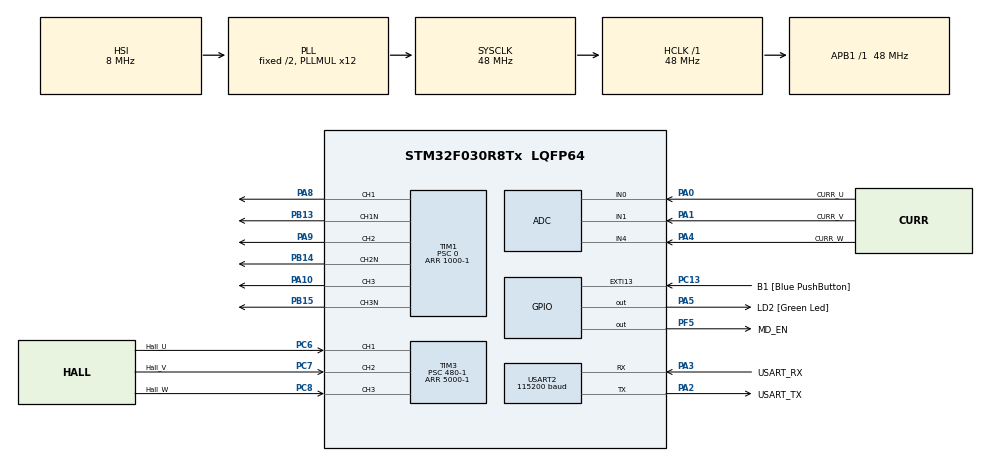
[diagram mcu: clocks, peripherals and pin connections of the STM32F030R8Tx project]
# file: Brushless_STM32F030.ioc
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ADC.ContinuousConvMode=DISABLE
ADC.DMAContinuousRequests=DISABLE
ADC.DiscontinuousConvMode=DISABLE
ADC.EOCSelection=ADC_EOC_SINGLE_CONV
ADC.ExternalTrigConv=ADC_EXTERNALTRIGCONV_T1_TRGO
ADC.ExternalTrigConvEdge=ADC_EXTERNALTRIGCONVEDGE_RISING
ADC.Overrun=ADC_OVR_DATA_OVERWRITTEN
ADC.SamplingTime=ADC_SAMPLETIME_1CYCLE_5
ADC.ScanConvMode=ADC_SCAN_DIRECTION_FORWARD
Mcu.Family=STM32F0
Mcu.Name=STM32F030R8Tx
Mcu.Package=LQFP64
NVIC.ADC1_IRQn=true\:2\:0\:true\:false\:true\:true\:true
NVIC.TIM3_IRQn=true\:0\:0\:false\:false\:true\:true\:true
NVIC.TIM6_IRQn=true\:3\:0\:true\:false\:true\:true\:true
NVIC.USART2_IRQn=true\:1\:0\:true\:false\:true\:true\:true
PA0.GPIO_Label=CURR_U
PA0.Mode=IN0
PA0.Signal=ADC_IN0
PA1.GPIO_Label=CURR_V
PA1.Mode=IN1
PA1.Signal=ADC_IN1
PA10.Signal=S_TIM1_CH3
PA13.GPIO_Label=TMS
PA13.Mode=Serial_Wire
PA13.Signal=SYS_SWDIO
PA14.GPIO_Label=TCK
PA14.Mode=Serial_Wire
PA14.Signal=SYS_SWCLK
PA2.GPIO_Label=USART_TX
PA2.GPIO_Mode=GPIO_MODE_AF_PP
PA2.GPIO_PuPd=GPIO_NOPULL
PA2.GPIO_Speed=GPIO_SPEED_FREQ_LOW
PA2.Mode=Asynchronous
PA2.Signal=USART2_TX
PA3.GPIO_Label=USART_RX
PA3.GPIO_Mode=GPIO_MODE_AF_PP
PA3.GPIO_PuPd=GPIO_NOPULL
PA3.GPIO_Speed=GPIO_SPEED_FREQ_LOW
PA3.Mode=Asynchronous
PA3.Signal=USART2_RX
PA4.GPIO_Label=CURR_W
PA4.Mode=IN4
PA4.Signal=ADC_IN4
PA5.GPIO_Label=LD2 [Green Led]
PA5.GPIO_Mode=GPIO_MODE_OUTPUT_PP
PA5.GPIO_PuPd=GPIO_NOPULL
PA5.GPIO_Speed=GPIO_SPEED_FREQ_LOW
PA5.Signal=GPIO_Output
PA8.Signal=S_TIM1_CH1
PA9.Signal=S_TIM1_CH2
PB13.Mode=PWM Generation1 CH1 CH1N
PB13.Signal=TIM1_CH1N
PB14.Mode=PWM Generation2 CH2 CH2N
PB14.Signal=TIM1_CH2N
PB15.Mode=PWM Generation3 CH3 CH3N
PB15.Signal=TIM1_CH3N
PC13.GPIO_Label=B1 [Blue PushButton]
PC13.GPIO_ModeDefaultEXTI=GPIO_MODE_IT_FALLING
PC13.Signal=GPXTI13
PC14-OSC32_IN.Mode=LSE-External-Oscillator
PC14-OSC32_IN.Signal=RCC_OSC32_IN
PC15-OSC32_OUT.Mode=LSE-External-Oscillator
PC15-OSC32_OUT.Signal=RCC_OSC32_OUT
PC6.GPIO_Label=Hall_U
PC6.GPIO_ModeDefaultPP=GPIO_MODE_AF_OD
PC6.GPIO_PuPd=GPIO_PULLUP
PC6.Signal=S_TIM3_CH1
PC7.GPIO_Label=Hall_V
PC7.GPIO_ModeDefaultPP=GPIO_MODE_AF_OD
PC7.GPIO_PuPd=GPIO_PULLUP
PC7.Signal=S_TIM3_CH2
PC8.GPIO_Label=Hall_W
PC8.GPIO_ModeDefaultPP=GPIO_MODE_AF_OD
PC8.GPIO_PuPd=GPIO_PULLUP
PC8.Signal=S_TIM3_CH3
PF0-OSC_IN.Mode=HSE-External-Clock-Source
PF0-OSC_IN.Signal=RCC_OSC_IN
PF1-OSC_OUT.Signal=RCC_OSC_OUT
PF5.GPIO_Label=MD_EN
PF5.Signal=GPIO_Output
ProjectManager.HeapSize=0x200
ProjectManager.StackSize=0x400
ProjectManager.TargetToolchain=EWARM V8.32
RCC.AHBFreq_Value=48000000
RCC.APB1Freq_Value=48000000
RCC.APB1TimFreq_Value=48000000
RCC.HCLKFreq_Value=48000000
RCC.PLLMUL=RCC_PLL_MUL12
RCC.SYSCLKFreq_VALUE=48000000
RCC.SYSCLKSource=RCC_SYSCLKSOURCE_PLLCLK
SH.S_TIM1_CH1.0=TIM1_CH1,PWM Generation1 CH1 CH1N
SH.S_TIM1_CH2.0=TIM1_CH2,PWM Generation2 CH2 CH2N
SH.S_TIM1_CH3.0=TIM1_CH3,PWM Generation3 CH3 CH3N
SH.S_TIM3_CH1.0=TIM3_CH1,Xored_Inputs_Hall_Sensor_Interface
SH.S_TIM3_CH2.0=TIM3_CH2,Xored_Inputs_Hall_Sensor_Interface
SH.S_TIM3_CH3.0=TIM3_CH3,Xored_Inputs_Hall_Sensor_Interface
TIM1.AutoReloadPreload=TIM_AUTORELOAD_PRELOAD_ENABLE
TIM1.Channel-PWM\ Generation1\ CH1\ CH1N=TIM_CHANNEL_1
TIM1.Channel-PWM\ Generation2\ CH2\ CH2N=TIM_CHANNEL_2
TIM1.Channel-PWM\ Generation3\ CH3\ CH3N=TIM_CHANNEL_3
TIM1.CounterMode=TIM_COUNTERMODE_CENTERALIGNED1
TIM1.Period=1000-1
TIM1.Prescaler=0
TIM1.TIM_MasterOutputTrigger=TIM_TRGO_UPDATE
TIM3.IC1Filter=5
TIM3.Period=5000-1
TIM3.Prescaler=480-1
TIM6.AutoReloadPreload=TIM_AUTORELOAD_PRELOAD_ENABLE
TIM6.Period=10000-1
TIM6.Prescaler=48-1
USART2.BaudRate=115200
USART2.DMADisableonRxErrorParam=ADVFEATURE_DMA_DISABLEONRXERROR
USART2.VirtualMode-Asynchronous=VM_ASYNC
VP_TIM6_VS_ClockSourceINT.Mode=Enable_Timer
board=NUCLEO-F030R8

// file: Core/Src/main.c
/* USER CODE BEGIN Header */
/**
  ******************************************************************************
  * @file           : main.c
  * @brief          : Main program body
  ******************************************************************************
  * @attention
  *
  * <h2><center>&copy; Copyright (c) 2021 STMicroelectronics.
  * All rights reserved.</center></h2>
  *
  * This software component is licensed by ST under BSD 3-Clause license,
  * the "License"; You may not use this file except in compliance with the
  * License. You may obtain a copy of the License at:
  *                        opensource.org/licenses/BSD-3-Clause
  *
  ******************************************************************************
  */
/* USER CODE END Header */
#include "main.h"

/* USER CODE BEGIN Includes */
#include	"Common/Control.h"
#include	"Common/Communication/Communication.h"

#include	"Interface/ML_ADC.h"
#include	"Interface/ML_TIM.h"

/* USER CODE END Includes */

ADC_HandleTypeDef hadc;

TIM_HandleTypeDef htim1;
TIM_HandleTypeDef htim3;
TIM_HandleTypeDef htim6;

UART_HandleTypeDef huart2;

void SystemClock_Config(void);
static void MX_GPIO_Init(void);
static void MX_USART2_UART_Init(void);
static void MX_TIM1_Init(void);
static void MX_TIM3_Init(void);
static void MX_ADC_Init(void);
static void MX_TIM6_Init(void);

int main(void)
{

  /* MCU Configuration--------------------------------------------------------*/

  /* Reset of all peripherals, Initializes the Flash interface and the Systick. */
  HAL_Init();

  /* Configure the system clock */
  SystemClock_Config();

  /* Initialize all configured peripherals */
  MX_GPIO_Init();
  MX_USART2_UART_Init();
  MX_TIM1_Init();
  MX_TIM3_Init();
  MX_ADC_Init();
  MX_TIM6_Init();
  /* USER CODE BEGIN 2 */

	/* Startup */
	TIM_Startup();
	ADC_Startup();

	Ctr_Startup();
	Com_Startup();

  /* USER CODE END 2 */

  /* Infinite loop */
  while (1)
  {

    /* USER CODE BEGIN 3 */
	//Ctr_Task();
	Com_Task();

  }
  /* USER CODE END 3 */
}

void SystemClock_Config(void)
{
  RCC_OscInitTypeDef RCC_OscInitStruct = {0};
  RCC_ClkInitTypeDef RCC_ClkInitStruct = {0};

  /** Initializes the RCC Oscillators according to the specified parameters
  * in the RCC_OscInitTypeDef structure.
  */
  RCC_OscInitStruct.OscillatorType = RCC_OSCILLATORTYPE_HSI|RCC_OSCILLATORTYPE_HSI14;
  RCC_OscInitStruct.HSIState = RCC_HSI_ON;
  RCC_OscInitStruct.HSI14State = RCC_HSI14_ON;
  RCC_OscInitStruct.HSICalibrationValue = RCC_HSICALIBRATION_DEFAULT;
  RCC_OscInitStruct.HSI14CalibrationValue = 16;
  RCC_OscInitStruct.PLL.PLLState = RCC_PLL_ON;
  RCC_OscInitStruct.PLL.PLLSource = RCC_PLLSOURCE_HSI;
  RCC_OscInitStruct.PLL.PLLMUL = RCC_PLL_MUL12;
  RCC_OscInitStruct.PLL.PREDIV = RCC_PREDIV_DIV1;
  if (HAL_RCC_OscConfig(&RCC_OscInitStruct) != HAL_OK)
  {
    Error_Handler();
  }
  /** Initializes the CPU, AHB and APB buses clocks
  */
  RCC_ClkInitStruct.ClockType = RCC_CLOCKTYPE_HCLK|RCC_CLOCKTYPE_SYSCLK
                              |RCC_CLOCKTYPE_PCLK1;
  RCC_ClkInitStruct.SYSCLKSource = RCC_SYSCLKSOURCE_PLLCLK;
  RCC_ClkInitStruct.AHBCLKDivider = RCC_SYSCLK_DIV1;
  RCC_ClkInitStruct.APB1CLKDivider = RCC_HCLK_DIV1;

  if (HAL_RCC_ClockConfig(&RCC_ClkInitStruct, FLASH_LATENCY_1) != HAL_OK)
  {
    Error_Handler();
  }
}

static void MX_ADC_Init(void)
{

  ADC_ChannelConfTypeDef sConfig = {0};

  /** Configure the global features of the ADC (Clock, Resolution, Data Alignment and number of conversion)
  */
  hadc.Instance = ADC1;
  hadc.Init.ClockPrescaler = ADC_CLOCK_ASYNC_DIV1;
  hadc.Init.Resolution = ADC_RESOLUTION_12B;
  hadc.Init.DataAlign = ADC_DATAALIGN_RIGHT;
  hadc.Init.ScanConvMode = ADC_SCAN_DIRECTION_FORWARD;
  hadc.Init.EOCSelection = ADC_EOC_SINGLE_CONV;
  hadc.Init.LowPowerAutoWait = DISABLE;
  hadc.Init.LowPowerAutoPowerOff = DISABLE;
  hadc.Init.ContinuousConvMode = DISABLE;
  hadc.Init.DiscontinuousConvMode = DISABLE;
  hadc.Init.ExternalTrigConv = ADC_EXTERNALTRIGCONV_T1_TRGO;
  hadc.Init.ExternalTrigConvEdge = ADC_EXTERNALTRIGCONVEDGE_RISING;
  hadc.Init.DMAContinuousRequests = DISABLE;
  hadc.Init.Overrun = ADC_OVR_DATA_OVERWRITTEN;
  if (HAL_ADC_Init(&hadc) != HAL_OK)
  {
    Error_Handler();
  }
  /** Configure for the selected ADC regular channel to be converted.
  */
  sConfig.Channel = ADC_CHANNEL_0;
  sConfig.Rank = ADC_RANK_CHANNEL_NUMBER;
  sConfig.SamplingTime = ADC_SAMPLETIME_1CYCLE_5;
  if (HAL_ADC_ConfigChannel(&hadc, &sConfig) != HAL_OK)
  {
    Error_Handler();
  }
  /** Configure for the selected ADC regular channel to be converted.
  */
  sConfig.Channel = ADC_CHANNEL_1;
  if (HAL_ADC_ConfigChannel(&hadc, &sConfig) != HAL_OK)
  {
    Error_Handler();
  }
  /** Configure for the selected ADC regular channel to be converted.
  */
  sConfig.Channel = ADC_CHANNEL_4;
  if (HAL_ADC_ConfigChannel(&hadc, &sConfig) != HAL_OK)
  {
    Error_Handler();
  }

}

static void MX_TIM1_Init(void)
{

  TIM_MasterConfigTypeDef sMasterConfig = {0};
  TIM_OC_InitTypeDef sConfigOC = {0};
  TIM_BreakDeadTimeConfigTypeDef sBreakDeadTimeConfig = {0};

  htim1.Instance = TIM1;
  htim1.Init.Prescaler = 0;
  htim1.Init.CounterMode = TIM_COUNTERMODE_CENTERALIGNED1;
  htim1.Init.Period = 1000-1;
  htim1.Init.ClockDivision = TIM_CLOCKDIVISION_DIV1;
  htim1.Init.RepetitionCounter = 0;
  htim1.Init.AutoReloadPreload = TIM_AUTORELOAD_PRELOAD_ENABLE;
  if (HAL_TIM_PWM_Init(&htim1) != HAL_OK)
  {
    Error_Handler();
  }
  sMasterConfig.MasterOutputTrigger = TIM_TRGO_UPDATE;
  sMasterConfig.MasterSlaveMode = TIM_MASTERSLAVEMODE_DISABLE;
  if (HAL_TIMEx_MasterConfigSynchronization(&htim1, &sMasterConfig) != HAL_OK)
  {
    Error_Handler();
  }
  sConfigOC.OCMode = TIM_OCMODE_PWM1;
  sConfigOC.Pulse = 0;
  sConfigOC.OCPolarity = TIM_OCPOLARITY_HIGH;
  sConfigOC.OCNPolarity = TIM_OCNPOLARITY_HIGH;
  sConfigOC.OCFastMode = TIM_OCFAST_DISABLE;
  sConfigOC.OCIdleState = TIM_OCIDLESTATE_RESET;
  sConfigOC.OCNIdleState = TIM_OCNIDLESTATE_RESET;
  if (HAL_TIM_PWM_ConfigChannel(&htim1, &sConfigOC, TIM_CHANNEL_1) != HAL_OK)
  {
    Error_Handler();
  }
  if (HAL_TIM_PWM_ConfigChannel(&htim1, &sConfigOC, TIM_CHANNEL_2) != HAL_OK)
  {
    Error_Handler();
  }
  if (HAL_TIM_PWM_ConfigChannel(&htim1, &sConfigOC, TIM_CHANNEL_3) != HAL_OK)
  {
    Error_Handler();
  }
  sBreakDeadTimeConfig.OffStateRunMode = TIM_OSSR_DISABLE;
  sBreakDeadTimeConfig.OffStateIDLEMode = TIM_OSSI_DISABLE;
  sBreakDeadTimeConfig.LockLevel = TIM_LOCKLEVEL_OFF;
  sBreakDeadTimeConfig.DeadTime = 0;
  sBreakDeadTimeConfig.BreakState = TIM_BREAK_DISABLE;
  sBreakDeadTimeConfig.BreakPolarity = TIM_BREAKPOLARITY_HIGH;
  sBreakDeadTimeConfig.AutomaticOutput = TIM_AUTOMATICOUTPUT_DISABLE;
  if (HAL_TIMEx_ConfigBreakDeadTime(&htim1, &sBreakDeadTimeConfig) != HAL_OK)
  {
    Error_Handler();
  }
  HAL_TIM_MspPostInit(&htim1);

}

static void MX_TIM3_Init(void)
{

  TIM_HallSensor_InitTypeDef sConfig = {0};
  TIM_MasterConfigTypeDef sMasterConfig = {0};

  htim3.Instance = TIM3;
  htim3.Init.Prescaler = 480-1;
  htim3.Init.CounterMode = TIM_COUNTERMODE_UP;
  htim3.Init.Period = 5000-1;
  htim3.Init.ClockDivision = TIM_CLOCKDIVISION_DIV1;
  htim3.Init.AutoReloadPreload = TIM_AUTORELOAD_PRELOAD_DISABLE;
  sConfig.IC1Polarity = TIM_ICPOLARITY_RISING;
  sConfig.IC1Prescaler = TIM_ICPSC_DIV1;
  sConfig.IC1Filter = 5;
  sConfig.Commutation_Delay = 0;
  if (HAL_TIMEx_HallSensor_Init(&htim3, &sConfig) != HAL_OK)
  {
    Error_Handler();
  }
  sMasterConfig.MasterOutputTrigger = TIM_TRGO_OC2REF;
  sMasterConfig.MasterSlaveMode = TIM_MASTERSLAVEMODE_DISABLE;
  if (HAL_TIMEx_MasterConfigSynchronization(&htim3, &sMasterConfig) != HAL_OK)
  {
    Error_Handler();
  }

}

static void MX_TIM6_Init(void)
{

  htim6.Instance = TIM6;
  htim6.Init.Prescaler = 48-1;
  htim6.Init.CounterMode = TIM_COUNTERMODE_UP;
  htim6.Init.Period = 10000-1;
  htim6.Init.AutoReloadPreload = TIM_AUTORELOAD_PRELOAD_ENABLE;
  if (HAL_TIM_Base_Init(&htim6) != HAL_OK)
  {
    Error_Handler();
  }

}

static void MX_USART2_UART_Init(void)
{

  huart2.Instance = USART2;
  huart2.Init.BaudRate = 115200;
  huart2.Init.WordLength = UART_WORDLENGTH_8B;
  huart2.Init.StopBits = UART_STOPBITS_1;
  huart2.Init.Parity = UART_PARITY_NONE;
  huart2.Init.Mode = UART_MODE_TX_RX;
  huart2.Init.HwFlowCtl = UART_HWCONTROL_NONE;
  huart2.Init.OverSampling = UART_OVERSAMPLING_16;
  huart2.Init.OneBitSampling = UART_ONE_BIT_SAMPLE_DISABLE;
  huart2.AdvancedInit.AdvFeatureInit = UART_ADVFEATURE_DMADISABLEONERROR_INIT;
  huart2.AdvancedInit.DMADisableonRxError = UART_ADVFEATURE_DMA_DISABLEONRXERROR;
  if (HAL_UART_Init(&huart2) != HAL_OK)
  {
    Error_Handler();
  }

}

static void MX_GPIO_Init(void)
{
  GPIO_InitTypeDef GPIO_InitStruct = {0};

  /* GPIO Ports Clock Enable */
  __HAL_RCC_GPIOC_CLK_ENABLE();
  __HAL_RCC_GPIOF_CLK_ENABLE();
  __HAL_RCC_GPIOA_CLK_ENABLE();
  __HAL_RCC_GPIOB_CLK_ENABLE();

  /*Configure GPIO pin Output Level */
  HAL_GPIO_WritePin(MD_EN_GPIO_Port, MD_EN_Pin, GPIO_PIN_RESET);

  /*Configure GPIO pin Output Level */
  HAL_GPIO_WritePin(LD2_GPIO_Port, LD2_Pin, GPIO_PIN_RESET);

  /*Configure GPIO pin : B1_Pin */
  GPIO_InitStruct.Pin = B1_Pin;
  GPIO_InitStruct.Mode = GPIO_MODE_IT_FALLING;
  GPIO_InitStruct.Pull = GPIO_NOPULL;
  HAL_GPIO_Init(B1_GPIO_Port, &GPIO_InitStruct);

  /*Configure GPIO pin : MD_EN_Pin */
  GPIO_InitStruct.Pin = MD_EN_Pin;
  GPIO_InitStruct.Mode = GPIO_MODE_OUTPUT_PP;
  GPIO_InitStruct.Pull = GPIO_NOPULL;
  GPIO_InitStruct.Speed = GPIO_SPEED_FREQ_LOW;
  HAL_GPIO_Init(MD_EN_GPIO_Port, &GPIO_InitStruct);

  /*Configure GPIO pin : LD2_Pin */
  GPIO_InitStruct.Pin = LD2_Pin;
  GPIO_InitStruct.Mode = GPIO_MODE_OUTPUT_PP;
  GPIO_InitStruct.Pull = GPIO_NOPULL;
  GPIO_InitStruct.Speed = GPIO_SPEED_FREQ_LOW;
  HAL_GPIO_Init(LD2_GPIO_Port, &GPIO_InitStruct);

}

void Error_Handler(void)
{
  __disable_irq();
  while (1)
  {
  }
}

/************************ (C) COPYRIGHT STMicroelectronics *****END OF FILE****/
